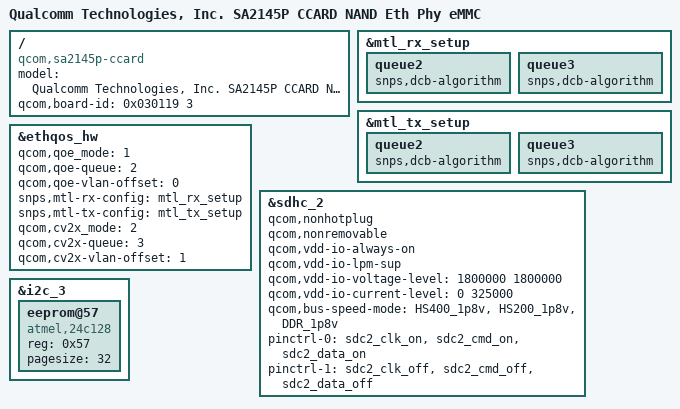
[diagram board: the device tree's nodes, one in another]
/* Copyright (c) 2020, The Linux Foundation. All rights reserved.
 *
 * This program is free software; you can redistribute it and/or modify
 * it under the terms of the GNU General Public License version 2 and
 * only version 2 as published by the Free Software Foundation.
 *
 * This program is distributed in the hope that it will be useful,
 * but WITHOUT ANY WARRANTY; without even the implied warranty of
 * MERCHANTABILITY or FITNESS FOR A PARTICULAR PURPOSE.  See the
 * GNU General Public License for more details.
 */

/dts-v1/;

#include "qcs403.dtsi"
#include "sa2150p-ccard.dtsi"
#include "sa2145p-ccard.dtsi"

/ {
	model = "Qualcomm Technologies, Inc. SA2145P CCARD NAND Eth Phy eMMC";
	compatible = "qcom,sa2145p-ccard", "qcom,qcs403", "qcom,sa2145p",
				"qcom,ccard";
	qcom,board-id = <0x030119 3>;
};

&mtl_rx_setup {
	queue2 {
		snps,dcb-algorithm;
	};

	queue3 {
		snps,dcb-algorithm;
	};
};

&mtl_tx_setup {
	queue2 {
		snps,dcb-algorithm;
	};

	queue3 {
		snps,dcb-algorithm;
	};
};

&ethqos_hw {
	qcom,qoe_mode = <1>;
	qcom,qoe-queue = <2>;
	qcom,qoe-vlan-offset = <0>;
	snps,mtl-rx-config = <&mtl_rx_setup>;
	snps,mtl-tx-config = <&mtl_tx_setup>;
	qcom,cv2x_mode = <2>;
	qcom,cv2x-queue = <3>;
	qcom,cv2x-vlan-offset = <1>;
};

&sdhc_2 {
	/delete-property/ cd-gpios;
	qcom,nonhotplug;
	qcom,nonremovable;

	qcom,vdd-io-always-on;
	qcom,vdd-io-lpm-sup;
	qcom,vdd-io-voltage-level = <1800000 1800000>;
	qcom,vdd-io-current-level = <0 325000>;

	qcom,bus-speed-mode = "HS400_1p8v", "HS200_1p8v", "DDR_1p8v";

	pinctrl-0 = <&sdc2_clk_on  &sdc2_cmd_on &sdc2_data_on>;
	pinctrl-1 = <&sdc2_clk_off &sdc2_cmd_off &sdc2_data_off>;
};

&i2c_3 {
	status = "okay";

	eeprom@57 {
		compatible = "atmel,24c128";
		reg = <0x57>;
		pagesize = <32>;
	};
};

